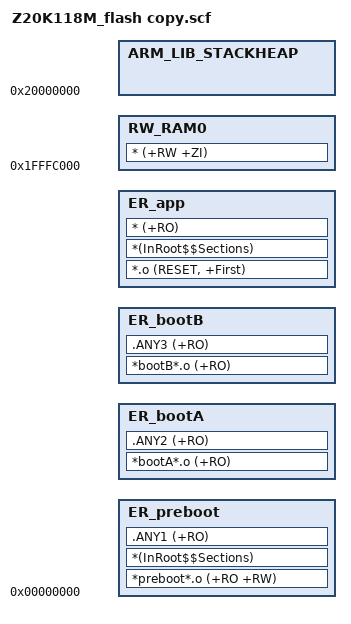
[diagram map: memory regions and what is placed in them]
; *************************************************************
; Scatter-Loading Description File (修正版)
; *************************************************************

#define PFLASH_START    0x00000000
#define PFLASH_SIZE     0x00040000      ; 256 KB

#define PREBOOT_START   PFLASH_START
#define PREBOOT_SIZE    0x00009000      ; 36 KB

#define BOOTA_START     (PREBOOT_START + PREBOOT_SIZE)   ; 0x00009000
#define BOOTA_SIZE      0x0000C800      ; 50 KB

#define BOOTB_START     (BOOTA_START + BOOTA_SIZE)       ; 0x00015800
#define BOOTB_SIZE      0x0000C800      ; 50 KB

#define APP_START       (BOOTB_START + BOOTB_SIZE)       ; 0x00022000
#define APP_SIZE        (PFLASH_START + PFLASH_SIZE - APP_START)  ; 120 KB = 0x1E000

#define RAM0_START      0x1FFFC000
#define RAM0_SIZE       0x00004000      ; 16 KB

#define RAM1_START      0x20000000
#define RAM1_SIZE       0x00004000      ; 16 KB

LR_IROM1 PFLASH_START PFLASH_SIZE
{
  ; ───────────── preboot ─────────────
  ER_preboot PREBOOT_START PREBOOT_SIZE
  {
      *preboot*.o (+RO +RW)           ; 建议明确分组，不要依赖 .ANY
      *(InRoot$$Sections)
      .ANY1 (+RO)                     ; 实在要兜底才用 .ANY1
  }

  ; ───────────── bootA ─────────────
  ER_bootA BOOTA_START BOOTA_SIZE
  {
      *bootA*.o (+RO)                 ; 建议用更精确的通配符或文件组
      .ANY2 (+RO)
  }

  ; ───────────── bootB ─────────────
  ER_bootB BOOTB_START BOOTB_SIZE
  {
      *bootB*.o (+RO)                 ; 同上，建议分开命名
      .ANY3 (+RO)
  }

  ; ───────────── application ─────────────
  ER_app APP_START APP_SIZE
  {
      *.o (RESET, +First)             ; 中断向量表（通常叫 RESET 或 .intvec）
      *(InRoot$$Sections)
      * (+RO)                         ; 所有剩余只读（code + const data）
  }

  ; ───────────── RAM sections ─────────────
  RW_RAM0 RAM0_START RAM0_SIZE
  {
      * (+RW +ZI)                     ; 通常把所有 RW/ZI 放在一起，除非你明确要分开
  }

  ; 如果你真的要用两个 RAM 块，可以分开写，但多数情况只用一个就够
  ; RW_RAM1 RAM1_START RAM1_SIZE
  ; {
  ;     .ANY (+RW +ZI -RW_RAM0)
  ; }

  ; 栈（从高地址向下生长）
  ARM_LIB_STACKHEAP RAM1_START RAM1_SIZE
  {
      ; 自动把栈放在高地址，堆放在低地址
      ; 也可以手动指定：
      ; Stack    +0x00000000  EMPTY  -0x1000   ; 4KB 栈
      ; Heap     +0x00000000  EMPTY  +0x2000   ; 8KB 堆（示例）
  }
}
